# CH32F20xxx register map
Vendor: WCH Ltd.; File version: 1.1
Registers are 32-bit, read-write, reset 0x0 unless marked. A register's access mark holds for its fields unless they carry their own. Offsets are from the block's base; [hi:lo] are bit positions; {n}, {i} and the like mark numbered series.

## PWR — Power control
Base 0x40007000
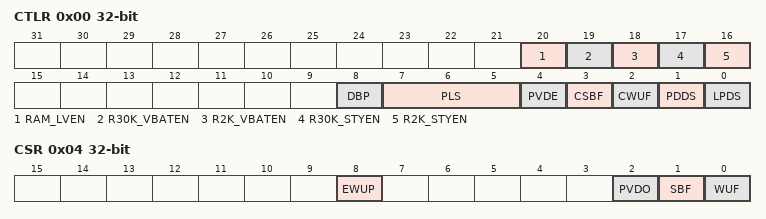
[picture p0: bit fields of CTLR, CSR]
0x00 CTLR — Power control register (PWR_CTRL)
  [20] RAM_LVEN — Ram LV Enable
  [19] R30K_VBATEN — VBAT 30k ram enable
  [18] R2K_VBATEN — VBAT 30k ram enable
  [17] R30K_STYEN — standby 30k ram enable
  [16] R2K_STYEN — standby 2k ram enable
  [8] DBP — Disable Backup Domain write protection
  [7:5] PLS — PVD Level Selection
  [4] PVDE — Power Voltage Detector Enable
  [3] CSBF — Clear STANDBY Flag
  [2] CWUF — Clear Wake-up Flag
  [1] PDDS — Power Down Deep Sleep
  [0] LPDS — Low Power Deep Sleep
0x04 CSR access per field — Power control register (PWR_CSR)
  [8] EWUP rw — Enable WKUP pin
  [2] PVDO ro — PVD Output
  [1] SBF ro — STANDBY Flag
  [0] WUF ro — Wake-Up Flag

## EXTEND — Extend configuration
Base 0x40023800
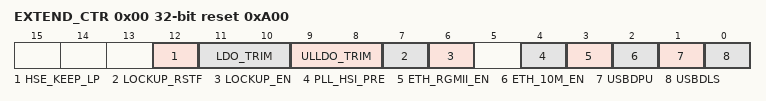
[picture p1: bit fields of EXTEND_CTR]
0x00 EXTEND_CTR access per field reset 0xA00 — EXTEND register
  [12] HSE_KEEP_LP rw
  [11:10] LDO_TRIM rw
  [9:8] ULLDO_TRIM rw
  [7] LOCKUP_RSTF read/clear — LOCKUP RESET
  [6] LOCKUP_EN rw — LOCKUP_Eable
  [4] PLL_HSI_PRE rw — Whether HSI is divided
  [3] ETH_RGMII_EN rw — ETH RGMII Enable
  [2] ETH_10M_EN rw — ETH 10M Enable
  [1] USBDPU rw — USBD pullup Enable
  [0] USBDLS rw — USBD Lowspeed Enable

## OPA — OPA configuration
Base 0x40023804
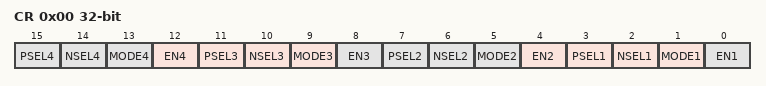
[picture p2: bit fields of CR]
0x00 CR — Control register
  [4n-1] PSEL{n} (n=1..4) — OPA PSEL{n}
  [4n-2] NSEL{n} (n=1..4) — OPA NSEL{n}
  [4n-3] MODE{n} (n=1..4) — OPA MODE{n}
  [12] EN4 — OPA Enable4
  [8] EN3 — OPA Eable3
  [4] EN2 — OPA Enable2
  [0] EN1 — OPA Enable1

## GPIOA — General purpose I/O
Base 0x40010800
Same registers: GPIOB 0x40010C00, GPIOC 0x40011000, GPIOD 0x40011400, GPIOE 0x40011800
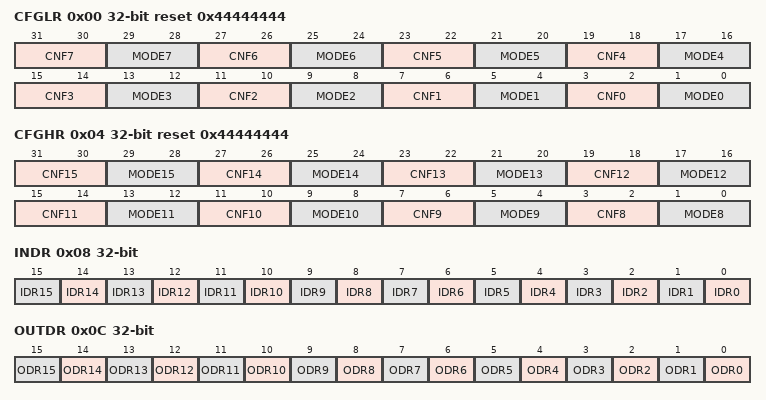
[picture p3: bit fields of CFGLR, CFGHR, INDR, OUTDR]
0x00 CFGLR reset 0x44444444 — Port configuration register low (GPIOn_CFGLR)
  [31:30] CNF7 — Port n.7 configuration bits
  [29:28] MODE7 — Port n.7 mode bits
  [27:26] CNF6 — Port n.6 configuration bits
  [25:24] MODE6 — Port n.6 mode bits
  [23:22] CNF5 — Port n.5 configuration bits
  [21:20] MODE5 — Port n.5 mode bits
  [19:18] CNF4 — Port n.4 configuration bits
  [17:16] MODE4 — Port n.4 mode bits
  [15:14] CNF3 — Port n.3 configuration bits
  [13:12] MODE3 — Port n.3 mode bits
  [11:10] CNF2 — Port n.2 configuration bits
  [9:8] MODE2 — Port n.2 mode bits
  [7:6] CNF1 — Port n.1 configuration bits
  [5:4] MODE1 — Port n.1 mode bits
  [3:2] CNF0 — Port n.0 configuration bits
  [1:0] MODE0 — Port n.0 mode bits
0x04 CFGHR reset 0x44444444 — Port configuration register high (GPIOn_CFGHR)
  [31:30] CNF15 — Port n.15 configuration bits
  [29:28] MODE15 — Port n.15 mode bits
  [27:26] CNF14 — Port n.14 configuration bits
  [25:24] MODE14 — Port n.14 mode bits
  [23:22] CNF13 — Port n.13 configuration bits
  [21:20] MODE13 — Port n.13 mode bits
  [19:18] CNF12 — Port n.12 configuration bits
  [17:16] MODE12 — Port n.12 mode bits
  [15:14] CNF11 — Port n.11 configuration bits
  [13:12] MODE11 — Port n.11 mode bits
  [11:10] CNF10 — Port n.10 configuration bits
  [9:8] MODE10 — Port n.10 mode bits
  [7:6] CNF9 — Port n.9 configuration bits
  [5:4] MODE9 — Port n.9 mode bits
  [3:2] CNF8 — Port n.8 configuration bits
  [1:0] MODE8 — Port n.8 mode bits
0x08 INDR ro — Port input data register (GPIOn_INDR)
  [n] IDR{n} (n=0..15) — Port input data
0x0C OUTDR — Port output data register (GPIOn_OUTDR)
  [n] ODR{n} (n=0..15) — Port output data
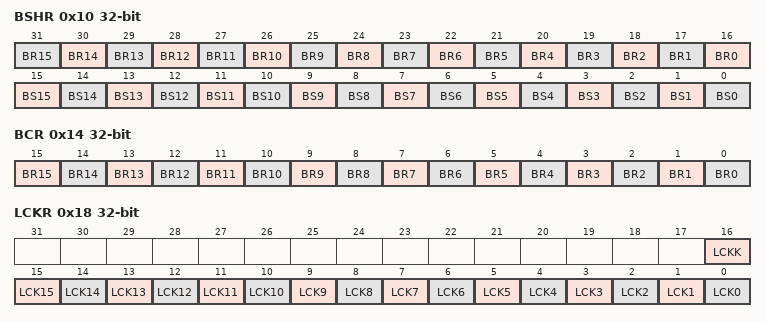
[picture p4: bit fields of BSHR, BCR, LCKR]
0x10 BSHR wo — Port bit set/reset register (GPIOn_BSHR)
  [n+16] BR{n} (n=0..15) — Reset bit {n}
  [n] BS{n} (n=3..15) — Set bit {n}
  [2] BS2 — Set bit 1
  [1] BS1 — Set bit 1
  [0] BS0 — Set bit 0
0x14 BCR wo — Port bit reset register (GPIOn_BCR)
  [n] BR{n} (n=3..15) — Reset bit {n}
  [2] BR2 — Reset bit 1
  [1] BR1 — Reset bit 1
  [0] BR0 — Reset bit 0
0x18 LCKR — Port configuration lock register
  [16] LCKK — Lock key
  [n] LCK{n} (n=0..15) — Port A Lock bit {n}
